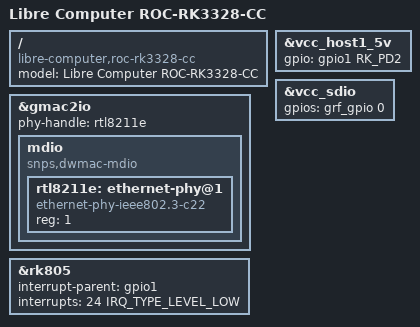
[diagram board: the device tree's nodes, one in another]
// SPDX-License-Identifier: (GPL-2.0+ OR MIT)
/*
 * Copyright (c) 2017 T-Chip Intelligent Technology Co., Ltd
 */

/dts-v1/;

#include <dt-bindings/input/input.h>
#include "rk3328-roc.dtsi"

/ {
	model = "Libre Computer ROC-RK3328-CC";
	compatible = "libre-computer,roc-rk3328-cc", "firefly,roc-rk3328-cc", "rockchip,rk3328";
};

/*
 * The RTL8211E is strapped to MDIO address 1 (PHYAD 001) and also answers at
 * the broadcast address 0. Without a PHY node the bus scan registers both,
 * the MAC attaches address 0, and on suspend address 1 (attached to nothing)
 * is powered down -- the one PHY with it, so the link drops and Wake-on-LAN
 * never sees its packet. Name the PHY so only it is registered.
 */
&gmac2io {
	phy-handle = <&rtl8211e>;

	mdio {
		compatible = "snps,dwmac-mdio";
		#address-cells = <1>;
		#size-cells = <0>;

		rtl8211e: ethernet-phy@1 {
			compatible = "ethernet-phy-ieee802.3-c22";
			reg = <1>;
		};
	};
};

&rk805 {
	interrupt-parent = <&gpio1>;
	interrupts = <24 IRQ_TYPE_LEVEL_LOW>;
};

&vcc_host1_5v {
	gpio = <&gpio1 RK_PD2 GPIO_ACTIVE_HIGH>;
};

&vcc_sdio {
	gpios = <&grf_gpio 0 GPIO_ACTIVE_HIGH>;
};
